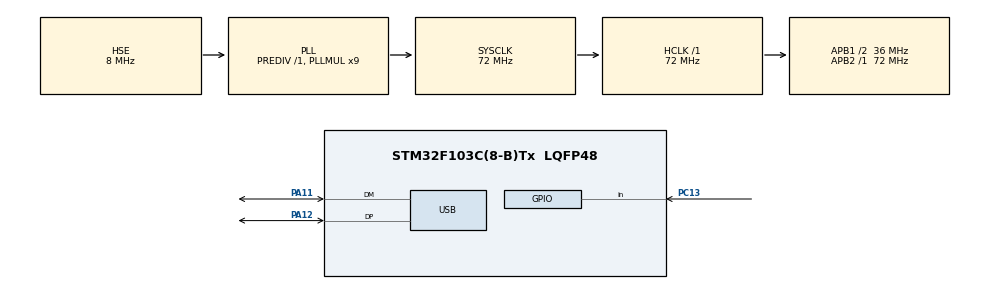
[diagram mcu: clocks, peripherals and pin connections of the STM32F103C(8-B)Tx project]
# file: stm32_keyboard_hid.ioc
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Mcu.Family=STM32F1
Mcu.Name=STM32F103C(8-B)Tx
Mcu.Package=LQFP48
NVIC.PriorityGroup=NVIC_PRIORITYGROUP_4
NVIC.USB_LP_CAN1_RX0_IRQn=true\:0\:0\:false\:false\:true\:false\:true
PA11.Mode=Device
PA11.Signal=USB_DM
PA12.Mode=Device
PA12.Signal=USB_DP
PA13.Mode=Serial_Wire
PA13.Signal=SYS_JTMS-SWDIO
PA14.Mode=Serial_Wire
PA14.Signal=SYS_JTCK-SWCLK
PC13-TAMPER-RTC.GPIO_PuPd=GPIO_PULLUP
PC13-TAMPER-RTC.Signal=GPIO_Input
PD0-OSC_IN.Mode=HSE-External-Oscillator
PD0-OSC_IN.Signal=RCC_OSC_IN
PD1-OSC_OUT.Mode=HSE-External-Oscillator
PD1-OSC_OUT.Signal=RCC_OSC_OUT
ProjectManager.HeapSize=0x200
ProjectManager.StackSize=0x400
ProjectManager.TargetToolchain=MDK-ARM V5.27
RCC.AHBFreq_Value=72000000
RCC.APB1CLKDivider=RCC_HCLK_DIV2
RCC.APB1Freq_Value=36000000
RCC.APB1TimFreq_Value=72000000
RCC.APB2Freq_Value=72000000
RCC.APB2TimFreq_Value=72000000
RCC.HCLKFreq_Value=72000000
RCC.PLLMUL=RCC_PLL_MUL9
RCC.SYSCLKFreq_VALUE=72000000
RCC.SYSCLKSource=RCC_SYSCLKSOURCE_PLLCLK
RCC.USBFreq_Value=48000000
RCC.USBPrescaler=RCC_USBCLKSOURCE_PLL_DIV1_5
USB_DEVICE.CLASS_NAME_FS=HID
USB_DEVICE.VirtualMode=Hid
USB_DEVICE.VirtualModeFS=Hid_FS
VP_IWDG_VS_IWDG.Mode=IWDG_Activate
VP_USB_DEVICE_VS_USB_DEVICE_HID_FS.Mode=HID_FS
board=custom

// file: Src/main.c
/* USER CODE BEGIN Header */
/**
  ******************************************************************************
  * @file           : main.c
  * @brief          : Main program body
  ******************************************************************************
  * @attention
  *
  * <h2><center>&copy; Copyright (c) 2020 STMicroelectronics.
  * All rights reserved.</center></h2>
  *
  * This software component is licensed by ST under Ultimate Liberty license
  * SLA0044, the "License"; You may not use this file except in compliance with
  * the License. You may obtain a copy of the License at:
  *                             www.st.com/SLA0044
  *
  ******************************************************************************
  */
/* USER CODE END Header */

#include "main.h"
#include "usb_device.h"

/* USER CODE BEGIN Includes */
#include "keycodes.h"
#include "usbd_hid.h"
/* USER CODE END Includes */

IWDG_HandleTypeDef hiwdg;

void SystemClock_Config(void);
static void MX_GPIO_Init(void);
static void MX_IWDG_Init(void);

/* USER CODE BEGIN 0 */
extern uint8_t key_buf[9];
extern USBD_HandleTypeDef hUsbDeviceFS;
extern volatile uint8_t PrevXferComplete;						//transfer complete flag

void KEYBOARD_SEND_key_buf(void)
{
	PrevXferComplete = 0;
	USBD_HID_SendReport(&hUsbDeviceFS, key_buf, sizeof(key_buf));
#if 0
	HAL_Delay(100);
#else
  while (!PrevXferComplete);	//wait till the end of transaction
#endif
}

void KEYBOARD_SEND_char(char ch)
{
	press_key(ch);
	KEYBOARD_SEND_key_buf();
	release_key();
	KEYBOARD_SEND_key_buf();
}

void KEYBOARD_SEND_string(char *wrd)
{
	do {
		KEYBOARD_SEND_char(*wrd);
	} while(*(++wrd));
}

//add up to 6 keys + mod to buffer (length - number of keys pressed simultaneously
void buf_keys_mod(uint8_t *keys, uint8_t length, uint8_t mod)	//add mod and key to buffer (allows to send F1-F12 keys, ESC and others)
{
	if(length>6) length = 6;							//no more than 6 keys allowed simultaneously
	for (uint8_t i=0; i<length;i++)
	{
		key_buf[3+i] = *(keys++);
	}
	key_buf[1] = mod;
}

//send up to 6 keys and mod
void KEYBOARD_SEND_Keys_Mod(uint8_t *keys,uint8_t keys_num, uint8_t mod)
{
	buf_keys_mod(keys, keys_num, mod);
	KEYBOARD_SEND_key_buf();
	release_key();
	KEYBOARD_SEND_key_buf();
}
/* USER CODE END 0 */

int main(void)
{
  /* MCU Configuration--------------------------------------------------------*/
  /* Reset of all peripherals, Initializes the Flash interface and the Systick. */
  HAL_Init();
  /* Configure the system clock */
  SystemClock_Config();
  /* Initialize all configured peripherals */
  MX_GPIO_Init();
  MX_IWDG_Init();
  MX_USB_DEVICE_Init();

  uint8_t key_codes[] = {KEY_O};
	_Bool button_released = 1;

  while (1)
  {
		HAL_IWDG_Refresh(&hiwdg);

		if ((HAL_GPIO_ReadPin(GPIOC, GPIO_PIN_13) == GPIO_PIN_SET) && button_released)
		{
			HAL_Delay(300);
			if (HAL_GPIO_ReadPin(GPIOC, GPIO_PIN_13) == GPIO_PIN_SET)
			{
				button_released = 0;	// Block sending key_code untill button_released
				KEYBOARD_SEND_Keys_Mod(key_codes, sizeof(key_codes), MOD_GUI);
			}
		}

		// Check button released
		if (!button_released)
		{
			if(HAL_GPIO_ReadPin(GPIOC, GPIO_PIN_13) == GPIO_PIN_RESET) button_released = 1;
		}
  }

}

void SystemClock_Config(void)
{
  RCC_OscInitTypeDef RCC_OscInitStruct = {0};
  RCC_ClkInitTypeDef RCC_ClkInitStruct = {0};
  RCC_PeriphCLKInitTypeDef PeriphClkInit = {0};

  /** Initializes the CPU, AHB and APB busses clocks
  */
  RCC_OscInitStruct.OscillatorType = RCC_OSCILLATORTYPE_LSI|RCC_OSCILLATORTYPE_HSE;
  RCC_OscInitStruct.HSEState = RCC_HSE_ON;
  RCC_OscInitStruct.HSEPredivValue = RCC_HSE_PREDIV_DIV1;
  RCC_OscInitStruct.HSIState = RCC_HSI_ON;
  RCC_OscInitStruct.LSIState = RCC_LSI_ON;
  RCC_OscInitStruct.PLL.PLLState = RCC_PLL_ON;
  RCC_OscInitStruct.PLL.PLLSource = RCC_PLLSOURCE_HSE;
  RCC_OscInitStruct.PLL.PLLMUL = RCC_PLL_MUL9;
  if (HAL_RCC_OscConfig(&RCC_OscInitStruct) != HAL_OK)
  {
    Error_Handler();
  }
  /** Initializes the CPU, AHB and APB busses clocks
  */
  RCC_ClkInitStruct.ClockType = RCC_CLOCKTYPE_HCLK|RCC_CLOCKTYPE_SYSCLK
                              |RCC_CLOCKTYPE_PCLK1|RCC_CLOCKTYPE_PCLK2;
  RCC_ClkInitStruct.SYSCLKSource = RCC_SYSCLKSOURCE_PLLCLK;
  RCC_ClkInitStruct.AHBCLKDivider = RCC_SYSCLK_DIV1;
  RCC_ClkInitStruct.APB1CLKDivider = RCC_HCLK_DIV2;
  RCC_ClkInitStruct.APB2CLKDivider = RCC_HCLK_DIV1;

  if (HAL_RCC_ClockConfig(&RCC_ClkInitStruct, FLASH_LATENCY_2) != HAL_OK)
  {
    Error_Handler();
  }
  PeriphClkInit.PeriphClockSelection = RCC_PERIPHCLK_USB;
  PeriphClkInit.UsbClockSelection = RCC_USBCLKSOURCE_PLL_DIV1_5;
  if (HAL_RCCEx_PeriphCLKConfig(&PeriphClkInit) != HAL_OK)
  {
    Error_Handler();
  }
}

static void MX_IWDG_Init(void)
{

  hiwdg.Instance = IWDG;
  hiwdg.Init.Prescaler = IWDG_PRESCALER_32;	//Ttick = 0.8 ms
  hiwdg.Init.Reload = 2047;									//Twdt = 1.6 s
  if (HAL_IWDG_Init(&hiwdg) != HAL_OK)
  {
    Error_Handler();
  }

}

static void MX_GPIO_Init(void)
{
  GPIO_InitTypeDef GPIO_InitStruct = {0};

  /* GPIO Ports Clock Enable */
  __HAL_RCC_GPIOC_CLK_ENABLE();
  __HAL_RCC_GPIOD_CLK_ENABLE();
  __HAL_RCC_GPIOA_CLK_ENABLE();

  /*Configure GPIO pin : PC13 */
  GPIO_InitStruct.Pin = GPIO_PIN_13;
  GPIO_InitStruct.Mode = GPIO_MODE_INPUT;
  GPIO_InitStruct.Pull = GPIO_PULLUP;
  HAL_GPIO_Init(GPIOC, &GPIO_InitStruct);

}

void Error_Handler(void)
{
}

/************************ (C) COPYRIGHT STMicroelectronics *****END OF FILE****/
